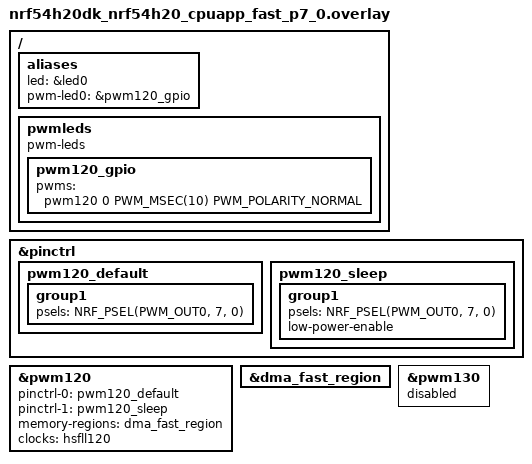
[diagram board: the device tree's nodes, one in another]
/*
 * Copyright (c) 2024 Nordic Semiconductor ASA
 *
 * SPDX-License-Identifier: LicenseRef-Nordic-5-Clause
 */

#include <zephyr/dt-bindings/pwm/pwm.h>

/ {
	aliases {
		led = &led0;
		/delete-property/ led1;
		pwm-led0 = &pwm120_gpio;
	};

	pwmleds {
		compatible = "pwm-leds";

		pwm120_gpio: pwm120_gpio {
			pwms = <&pwm120 0 PWM_MSEC(10) PWM_POLARITY_NORMAL>;
		};
	};
};

/delete-node/ &led1;

&pinctrl {
	/omit-if-no-ref/ pwm120_default: pwm120_default {
		group1 {
			psels = <NRF_PSEL(PWM_OUT0, 7, 0)>;
		};
	};

	/omit-if-no-ref/ pwm120_sleep: pwm120_sleep {
		group1 {
			psels = <NRF_PSEL(PWM_OUT0, 7, 0)>;
			low-power-enable;
		};
	};
};

&pwm120 {
	status = "okay";
	pinctrl-0 = <&pwm120_default>;
	pinctrl-1 = <&pwm120_sleep>;
	pinctrl-names = "default", "sleep";
	memory-regions = <&dma_fast_region>;
	clocks = <&hsfll120>;
};

&dma_fast_region {
	status = "okay";
};

&pwm130 {
	status = "disabled";
};
